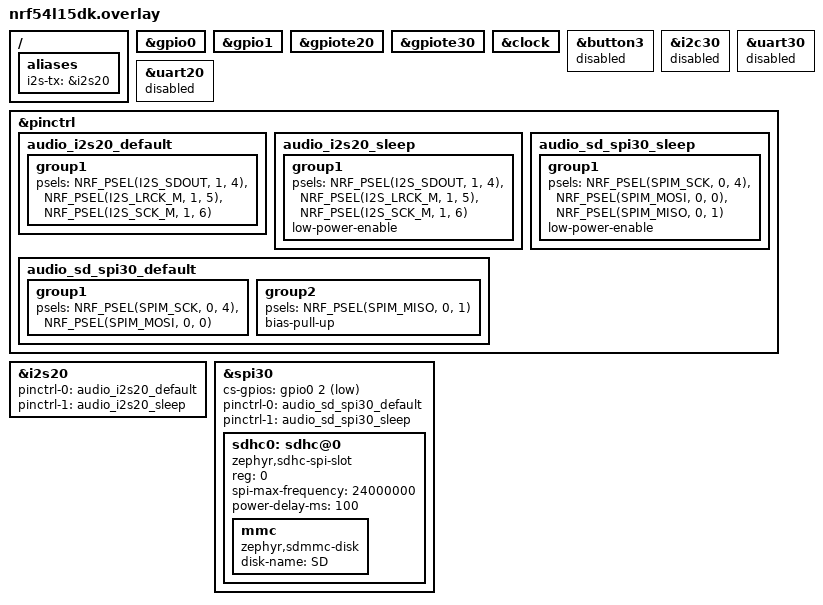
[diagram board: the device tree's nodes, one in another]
#include <zephyr/dt-bindings/gpio/gpio.h>
#include <zephyr/dt-bindings/pinctrl/nrf-pinctrl.h>

/ {
    aliases {
        i2s-tx = &i2s20;
    };
};

&gpio0 { status = "okay"; };
&gpio1 { status = "okay"; };
&gpiote20 { status = "okay"; };
&gpiote30 { status = "okay"; };
&clock { status = "okay"; };

/* P0 pins are used for SD SPI. */
&button3 { status = "disabled"; };
&i2c30 { status = "disabled"; };
&uart30 { status = "disabled"; };

&uart20 { status = "disabled"; };

&pinctrl {
    audio_i2s20_default: audio_i2s20_default {
        group1 {
            psels = <NRF_PSEL(I2S_SDOUT, 1, 4)>,
                    <NRF_PSEL(I2S_LRCK_M, 1, 5)>,
                    <NRF_PSEL(I2S_SCK_M, 1, 6)>;
        };
    };

    audio_i2s20_sleep: audio_i2s20_sleep {
        group1 {
            psels = <NRF_PSEL(I2S_SDOUT, 1, 4)>,
                    <NRF_PSEL(I2S_LRCK_M, 1, 5)>,
                    <NRF_PSEL(I2S_SCK_M, 1, 6)>;
            low-power-enable;
        };
    };

    audio_sd_spi30_default: audio_sd_spi30_default {
        group1 {
            psels = <NRF_PSEL(SPIM_SCK, 0, 4)>,
                    <NRF_PSEL(SPIM_MOSI, 0, 0)>;
        };
        group2 {
            psels = <NRF_PSEL(SPIM_MISO, 0, 1)>;
            bias-pull-up;
        };
    };

    audio_sd_spi30_sleep: audio_sd_spi30_sleep {
        group1 {
            psels = <NRF_PSEL(SPIM_SCK, 0, 4)>,
                    <NRF_PSEL(SPIM_MOSI, 0, 0)>,
                    <NRF_PSEL(SPIM_MISO, 0, 1)>;
            low-power-enable;
        };
    };
};

&i2s20 {
    status = "okay";
    pinctrl-0 = <&audio_i2s20_default>;
    pinctrl-1 = <&audio_i2s20_sleep>;
    pinctrl-names = "default", "sleep";
};

&spi30 {
    status = "okay";
    cs-gpios = <&gpio0 2 GPIO_ACTIVE_LOW>;
    pinctrl-0 = <&audio_sd_spi30_default>;
    pinctrl-1 = <&audio_sd_spi30_sleep>;
    pinctrl-names = "default", "sleep";

    sdhc0: sdhc@0 {
        compatible = "zephyr,sdhc-spi-slot";
        reg = <0>;
        status = "okay";
        spi-max-frequency = <24000000>;
        power-delay-ms = <100>;

        mmc {
            compatible = "zephyr,sdmmc-disk";
            disk-name = "SD";
            status = "okay";
        };
    };
};
